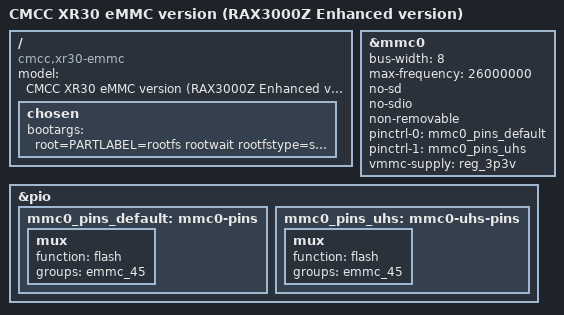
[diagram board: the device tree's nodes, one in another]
// SPDX-License-Identifier: GPL-2.0-or-later OR MIT

/dts-v1/;
#include "mt7981b-cmcc-xr30.dtsi"

/ {
	model = "CMCC XR30 eMMC version (RAX3000Z Enhanced version)";
	compatible = "cmcc,xr30-emmc", "mediatek,mt7981";

	chosen {
		bootargs = "root=PARTLABEL=rootfs rootwait rootfstype=squashfs,f2fs";
	};
};

&mmc0 {
	bus-width = <8>;
	max-frequency = <26000000>;
	no-sd;
	no-sdio;
	non-removable;
	pinctrl-names = "default", "state_uhs";
	pinctrl-0 = <&mmc0_pins_default>;
	pinctrl-1 = <&mmc0_pins_uhs>;
	vmmc-supply = <&reg_3p3v>;
	status = "okay";
};

&pio {
	mmc0_pins_default: mmc0-pins {
		mux {
			function = "flash";
			groups = "emmc_45";
		};
	};

	mmc0_pins_uhs: mmc0-uhs-pins {
		mux {
			function = "flash";
			groups = "emmc_45";
		};
	};
};
